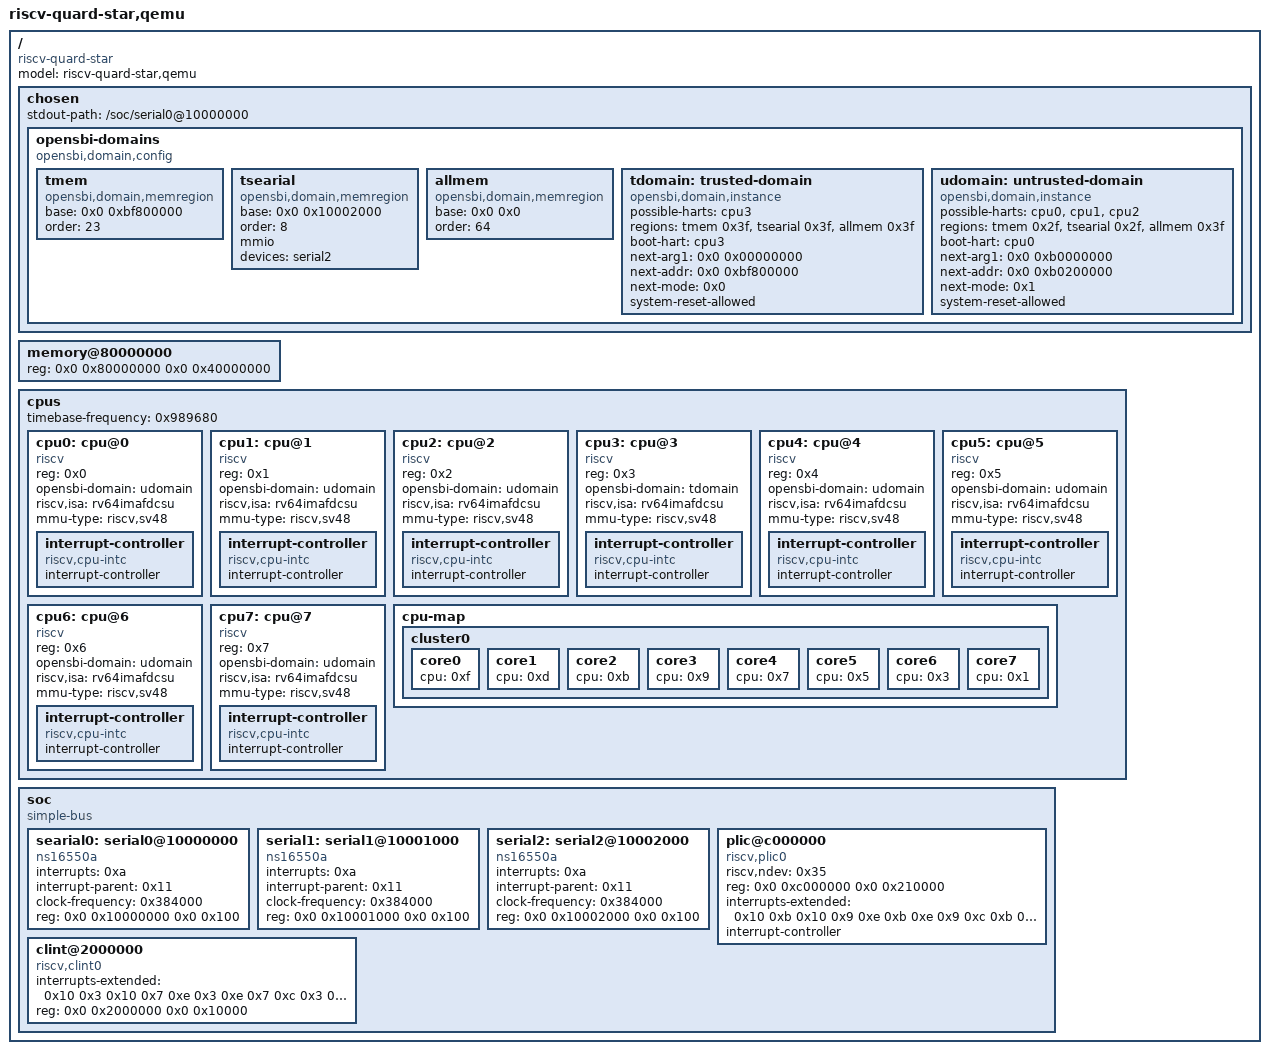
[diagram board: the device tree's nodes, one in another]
/dts-v1/;

/ {
	#address-cells = <0x2>;
	#size-cells = <0x2>;
	compatible = "riscv-quard-star";
	model = "riscv-quard-star,qemu";

	chosen {
		stdout-path = "/soc/serial0@10000000";

    /* https://github.com/riscv-software-src/opensbi/blob/master/docs/domain_support.md */
		opensbi-domains {                                                                     /* 域配置节点 */
      compatible = "opensbi,domain,config";                                               /* 域的兼容字符串 配置。 此 DT 属性应具有值 “opensbi、domain、config” */

      tmem: tmem {
        compatible = "opensbi,domain,memregion";                                          /* 域内存的兼容字符串 地区。 此 DT 属性应具有值 “opensbi、domain、memregion” */
        base = <0x0 0xbf800000>;                                                          /* (强制)——域内存区域的基地址。 这 DT 属性应该有一个 2 ^ 顺序 对齐的 64 位地址 */
        order = <23>;                                                                     /* 域内存区域的顺序。 这个DT 属性应在范围内具有 32 位值（即一个 DT 单元格） 3 <= 顺序 <= __riscv_xlen */
      };

      tsearial: tsearial {
        compatible = "opensbi,domain,memregion";
        base = <0x0 0x10002000>;
        order = <8>;
        mmio;                                                                             /* (可选)- 一个布尔标志，表示域是否 内存区域是内存映射 I/O (MMIO) 区域 */
        devices = <&serial2>;                                                             /* (可选)- 设备的设备 DT 节点 phandles 列表 属于这个域内存区域 */
      };

      allmem: allmem {
        compatible = "opensbi,domain,memregion";
        base = <0x0 0x0>;
        order = <64>;
      };

      tdomain: trusted-domain {
        compatible = "opensbi,domain,instance";                                           /* (强制)- 域实例的兼容字符串. 此 DT 属性应具有值 'opensbi,domain,instance' */
        possible-harts = <&cpu3>;                                                         /* (可选)- CPU DT 节点 phandles 的列表 域实例. 此列表代表了可能的 HART 域实例. */
        regions = <&tmem 0x3f>, <&tsearial 0x3f>, <&allmem 0x3f>;                         /* (可选)- 域内存区域列表 DT 节点 phandle 域实例的访问权限 */
        boot-hart = <&cpu3>;                                                              /* (可选)- 启动 HART 的 DT 节点 phandle 域实例. 如果将冷启动 HART 分配给域实例, 则此DT属性被忽略, 冷启动 HART 被假定为 启动域实例的 HART */
        next-arg1 = <0x0 0x00000000>;                                                     /* (可选)- 下级程序的参数 */
        next-addr = <0x0 0xbf800000>;                                                     /* (可选)- 下级程序的起始地址 */
        next-mode = <0x0>;                                                                /* (可选)- 下级程序的允许模式 0为U模式，1为S模式 */
        system-reset-allowed;                                                             /* (可选)- 一个布尔标志，表示 是否允许域实例进行系统重置. */
      };

      udomain: untrusted-domain {
        compatible = "opensbi,domain,instance";
        possible-harts = <&cpu0 &cpu1 &cpu2>;
        regions = <&tmem 0x2f>, <&tsearial 0x2f>, <&allmem 0x3f>;
        boot-hart = <&cpu0>;                                                              /* (可选)- 启动 HART 的 DT 节点 phandle 域实例. 如果将冷启动 HART 分配给域实例, 则此DT属性被忽略, 冷启动 HART 被假定为 启动域实例的 HART */
        next-arg1 = <0x0 0xb0000000>;
        next-addr = <0x0 0xb0200000>;
        next-mode = <0x1>;
        system-reset-allowed;                                                             /* (可选)- 一个布尔标志，表示 是否允许域实例进行系统重置. */
      };
		};
	};

	memory@80000000 {
		device_type = "memory";
		reg = <0x0 0x80000000 0x0 0x40000000>;
	};

	cpus {
		#address-cells = <0x1>;
		#size-cells = <0x0>;
		timebase-frequency = <0x989680>;

		cpu0: cpu@0 {
			phandle = <0xf>;
			device_type = "cpu";
			reg = <0x0>;
			status = "okay";
			compatible = "riscv";
      opensbi-domain = <&udomain>;
			riscv,isa = "rv64imafdcsu";
			mmu-type = "riscv,sv48";

			interrupt-controller {
        #address-cells = <0x1>;
				#interrupt-cells = <0x1>;
				interrupt-controller;
				compatible = "riscv,cpu-intc";
				phandle = <0x10>;
			};
		};

		cpu1: cpu@1 {
			phandle = <0xd>;
			device_type = "cpu";
			reg = <0x1>;
			status = "okay";
			compatible = "riscv";
      opensbi-domain = <&udomain>;
			riscv,isa = "rv64imafdcsu";
			mmu-type = "riscv,sv48";

			interrupt-controller {
        #address-cells = <0x1>;
				#interrupt-cells = <0x1>;
				interrupt-controller;
				compatible = "riscv,cpu-intc";
				phandle = <0xe>;
			};
		};

		cpu2: cpu@2 {
			phandle = <0xb>;
			device_type = "cpu";
			reg = <0x2>;
			status = "okay";
			compatible = "riscv";
      opensbi-domain = <&udomain>;
			riscv,isa = "rv64imafdcsu";
			mmu-type = "riscv,sv48";

			interrupt-controller {
        #address-cells = <0x1>;
				#interrupt-cells = <0x1>;
				interrupt-controller;
				compatible = "riscv,cpu-intc";
				phandle = <0xc>;
			};
		};

		cpu3: cpu@3 {
			phandle = <0x9>;
			device_type = "cpu";
			reg = <0x3>;
			status = "okay";
			compatible = "riscv";
      opensbi-domain = <&tdomain>;
			riscv,isa = "rv64imafdcsu";
			mmu-type = "riscv,sv48";

			interrupt-controller {
        #address-cells = <0x1>;
				#interrupt-cells = <0x1>;
				interrupt-controller;
				compatible = "riscv,cpu-intc";
				phandle = <0xa>;
			};
		};

		cpu4: cpu@4 {
			phandle = <0x7>;
			device_type = "cpu";
			reg = <0x4>;
			status = "okay";
			compatible = "riscv";
      opensbi-domain = <&udomain>;
			riscv,isa = "rv64imafdcsu";
			mmu-type = "riscv,sv48";

			interrupt-controller {
        #address-cells = <0x1>;
				#interrupt-cells = <0x1>;
				interrupt-controller;
				compatible = "riscv,cpu-intc";
				phandle = <0x8>;
			};
		};

		cpu5: cpu@5 {
			phandle = <0x5>;
			device_type = "cpu";
			reg = <0x5>;
			status = "okay";
			compatible = "riscv";
      opensbi-domain = <&udomain>;
			riscv,isa = "rv64imafdcsu";
			mmu-type = "riscv,sv48";

			interrupt-controller {
        #address-cells = <0x1>;
				#interrupt-cells = <0x1>;
				interrupt-controller;
				compatible = "riscv,cpu-intc";
				phandle = <0x6>;
			};
		};

		cpu6: cpu@6 {
			phandle = <0x3>;
			device_type = "cpu";
			reg = <0x6>;
			status = "okay";
			compatible = "riscv";
      opensbi-domain = <&udomain>;
			riscv,isa = "rv64imafdcsu";
			mmu-type = "riscv,sv48";

			interrupt-controller {
        #address-cells = <0x1>;
				#interrupt-cells = <0x1>;
				interrupt-controller;
				compatible = "riscv,cpu-intc";
				phandle = <0x4>;
			};
		};

		cpu7: cpu@7 {
			phandle = <0x1>;
			device_type = "cpu";
			reg = <0x7>;
			status = "okay";
			compatible = "riscv";
      opensbi-domain = <&udomain>;
			riscv,isa = "rv64imafdcsu";
			mmu-type = "riscv,sv48";

			interrupt-controller {
        #address-cells = <0x1>;
				#interrupt-cells = <0x1>;
				interrupt-controller;
				compatible = "riscv,cpu-intc";
				phandle = <0x2>;
			};
		};

		cpu-map {

			cluster0 {

				core0 {
					cpu = <0xf>;
				};

				core1 {
					cpu = <0xd>;
				};

				core2 {
					cpu = <0xb>;
				};

				core3 {
					cpu = <0x9>;
				};

				core4 {
					cpu = <0x7>;
				};

				core5 {
					cpu = <0x5>;
				};

				core6 {
					cpu = <0x3>;
				};

				core7 {
					cpu = <0x1>;
				};
			};
		};
	};

	soc {
		#address-cells = <0x2>;
		#size-cells = <0x2>;
		compatible = "simple-bus";
		ranges;

		searial0: serial0@10000000 {
			interrupts = <0xa>;
			interrupt-parent = <0x11>;
			clock-frequency = <0x384000>;
			reg = <0x0 0x10000000 0x0 0x100>;
			compatible = "ns16550a";
		};

		serial1: serial1@10001000 {
			interrupts = <0xa>;
			interrupt-parent = <0x11>;
			clock-frequency = <0x384000>;
			reg = <0x0 0x10001000 0x0 0x100>;
			compatible = "ns16550a";
		};

    serial2: serial2@10002000 {
			interrupts = <0xa>;
			interrupt-parent = <0x11>;
			clock-frequency = <0x384000>;
			reg = <0x0 0x10002000 0x0 0x100>;
			compatible = "ns16550a";
		};

    plic@c000000 {
			phandle = <0x11>;
			riscv,ndev = <0x35>;
			reg = <0x0 0xc000000 0x0 0x210000>;
			interrupts-extended = <0x10 0xb 0x10 0x9 0xe 0xb 0xe 0x9 0xc 0xb 0xc 0x9 0xa 0xb 0xa 0x9 0x8 0xb 0x8 0x9 0x6 0xb 0x6 0x9 0x4 0xb 0x4 0x9 0x2 0xb 0x2 0x9>;
			interrupt-controller;
			compatible = "riscv,plic0";
			#interrupt-cells = <0x1>;
			#address-cells = <0x0>;
		};

		clint@2000000 {
			interrupts-extended = <0x10 0x3 0x10 0x7 0xe 0x3 0xe 0x7 0xc 0x3 0xc 0x7 0xa 0x3 0xa 0x7 0x8 0x3 0x8 0x7 0x6 0x3 0x6 0x7 0x4 0x3 0x4 0x7 0x2 0x3 0x2 0x7>;
			reg = <0x0 0x2000000 0x0 0x10000>;
			compatible = "riscv,clint0";
		};
	};
};
